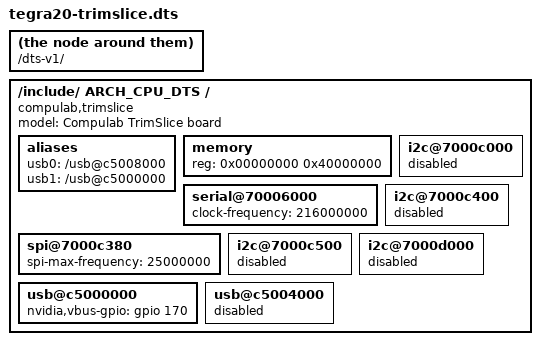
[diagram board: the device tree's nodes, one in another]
/dts-v1/;

/include/ ARCH_CPU_DTS

/ {
	model = "Compulab TrimSlice board";
	compatible = "compulab,trimslice", "nvidia,tegra20";

	aliases {
		usb0 = "/usb@c5008000";
		usb1 = "/usb@c5000000";
	};

	memory {
		reg = <0x00000000 0x40000000>;
	};

	serial@70006000 {
		clock-frequency = <216000000>;
	};

	i2c@7000c000 {
		status = "disabled";
	};

	spi@7000c380 {
		status = "okay";
		spi-max-frequency = <25000000>;
	};

	i2c@7000c400 {
		status = "disabled";
	};

	i2c@7000c500 {
		status = "disabled";
	};

	i2c@7000d000 {
		status = "disabled";
	};

	usb@c5000000 {
		nvidia,vbus-gpio = <&gpio 170 0>; /* PV2 */
	};

	usb@c5004000 {
		status = "disabled";
	};
};
